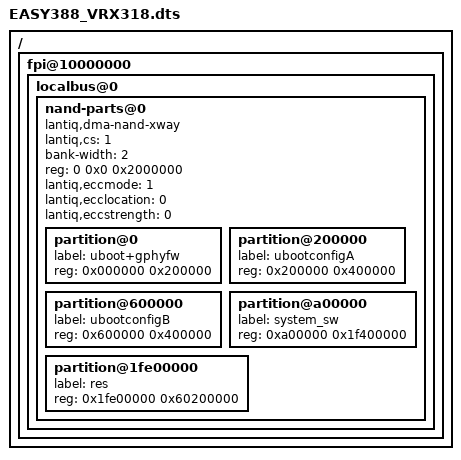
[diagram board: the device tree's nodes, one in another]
/dts-v1/;


/include/ "EASY388.dtsi"

/ {
	fpi@10000000 {
		localbus@0 {
			ranges = <0 0 0x4000000 0x3ffffff>;
			nand-parts@0 {
				compatible = "lantiq,dma-nand-xway";
				lantiq,cs = <1>;
				bank-width = <2>;
				reg = <0 0x0 0x2000000>;
				#address-cells = <1>;
				#size-cells = <1>;
				lantiq,eccmode = <1>;
				lantiq,ecclocation = <0>;
				lantiq,eccstrength = <0>;

				partition@0 {
					label = "uboot+gphyfw";
					reg = <0x000000 0x200000>;
				};

				partition@200000 {
					label = "ubootconfigA";
					reg = <0x200000 0x400000>;
				};

				partition@600000 {
					label = "ubootconfigB";
					reg = <0x600000 0x400000>;
				};

				partition@a00000 {
					label = "system_sw";
					reg = <0xa00000 0x1f400000>;
				};

				partition@1fe00000 {
					label = "res";
					reg = <0x1fe00000 0x60200000>;
				};

			};
		};
	};
};
